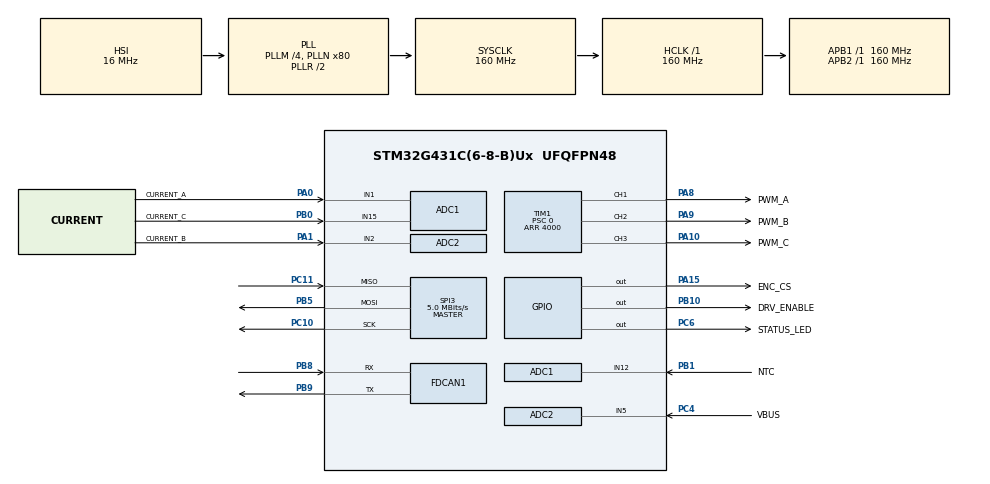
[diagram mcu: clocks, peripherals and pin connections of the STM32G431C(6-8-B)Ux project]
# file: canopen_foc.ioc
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ADC1.Channel-0\#ChannelRegularConversion=ADC_CHANNEL_1
ADC1.Channel-1\#ChannelRegularConversion=ADC_CHANNEL_15
ADC1.Channel-2\#ChannelRegularConversion=ADC_CHANNEL_12
ADC1.ClockPrescaler=ADC_CLOCK_SYNC_PCLK_DIV4
ADC1.DMAAccessMode=ADC_DMAACCESSMODE_12_10_BITS
ADC1.DMAContinuousRequests=ENABLE
ADC1.DiscontinuousConvMode=DISABLE
ADC1.EOCSelection=ADC_EOC_SEQ_CONV
ADC1.EnableInjectedConversion=ENABLE
ADC1.EnableRegularConversion=ENABLE
ADC1.ExternalTrigConv=ADC_EXTERNALTRIG_T1_TRGO
ADC1.ExternalTrigConvEdge=ADC_EXTERNALTRIGCONVEDGE_RISING
ADC1.ExternalTrigInjecConv=ADC_INJECTED_SOFTWARE_START
ADC1.ExternalTrigInjecConvEdge=ADC_EXTERNALTRIGINJECCONV_EDGE_NONE
ADC1.InjNumberOfConversion=2
ADC1.InjectedChannel-0\#ChannelInjectedConversion=ADC_CHANNEL_TEMPSENSOR_ADC1
ADC1.InjectedChannel-1\#ChannelInjectedConversion=ADC_CHANNEL_VREFINT
ADC1.InjectedOffsetNumber-0\#ChannelInjectedConversion=ADC_OFFSET_NONE
ADC1.InjectedOffsetNumber-1\#ChannelInjectedConversion=ADC_OFFSET_NONE
ADC1.InjectedRank-0\#ChannelInjectedConversion=1
ADC1.InjectedRank-1\#ChannelInjectedConversion=2
ADC1.InjectedSamplingTime-0\#ChannelInjectedConversion=ADC_SAMPLETIME_247CYCLES_5
ADC1.InjectedSamplingTime-1\#ChannelInjectedConversion=ADC_SAMPLETIME_247CYCLES_5
ADC1.Mode=ADC_DUALMODE_REGSIMULT
ADC1.NbrOfConversion=3
ADC1.NbrOfConversionFlag=1
ADC1.OffsetNumber-0\#ChannelRegularConversion=ADC_OFFSET_NONE
ADC1.OffsetNumber-1\#ChannelRegularConversion=ADC_OFFSET_NONE
ADC1.OffsetNumber-2\#ChannelRegularConversion=ADC_OFFSET_NONE
ADC1.Overrun=ADC_OVR_DATA_OVERWRITTEN
ADC1.Rank-0\#ChannelRegularConversion=1
ADC1.Rank-1\#ChannelRegularConversion=2
ADC1.Rank-2\#ChannelRegularConversion=3
ADC1.SamplingTime-0\#ChannelRegularConversion=ADC_SAMPLETIME_24CYCLES_5
ADC1.SamplingTime-1\#ChannelRegularConversion=ADC_SAMPLETIME_24CYCLES_5
ADC1.SamplingTime-2\#ChannelRegularConversion=ADC_SAMPLETIME_24CYCLES_5
ADC1.ScanConvMode=ADC_SCAN_ENABLE
ADC1.TwoSamplingDelay=ADC_TWOSAMPLINGDELAY_1CYCLE
ADC1.master=1
ADC2.Channel-0\#ChannelRegularConversion=ADC_CHANNEL_2
ADC2.Channel-1\#ChannelRegularConversion=ADC_CHANNEL_5
ADC2.Channel-2\#ChannelRegularConversion=ADC_CHANNEL_5
ADC2.ClockPrescaler=ADC_CLOCK_SYNC_PCLK_DIV4
ADC2.DMAContinuousRequests=ENABLE
ADC2.DiscontinuousConvMode=DISABLE
ADC2.EOCSelection=ADC_EOC_SEQ_CONV
ADC2.EnableRegularConversion=ENABLE
ADC2.ExternalTrigConv=ADC_SOFTWARE_START
ADC2.ExternalTrigConvEdge=ADC_EXTERNALTRIGCONVEDGE_NONE
ADC2.NbrOfConversion=3
ADC2.NbrOfConversionFlag=1
ADC2.OffsetNumber-0\#ChannelRegularConversion=ADC_OFFSET_NONE
ADC2.OffsetNumber-1\#ChannelRegularConversion=ADC_OFFSET_NONE
ADC2.OffsetNumber-2\#ChannelRegularConversion=ADC_OFFSET_NONE
ADC2.Overrun=ADC_OVR_DATA_OVERWRITTEN
ADC2.Rank-0\#ChannelRegularConversion=1
ADC2.Rank-1\#ChannelRegularConversion=2
ADC2.Rank-2\#ChannelRegularConversion=3
ADC2.SamplingTime-0\#ChannelRegularConversion=ADC_SAMPLETIME_24CYCLES_5
ADC2.SamplingTime-1\#ChannelRegularConversion=ADC_SAMPLETIME_24CYCLES_5
ADC2.SamplingTime-2\#ChannelRegularConversion=ADC_SAMPLETIME_24CYCLES_5
ADC2.ScanConvMode=ADC_SCAN_ENABLE
Dma.ADC1.0.Direction=DMA_PERIPH_TO_MEMORY
Dma.ADC1.0.EventEnable=DISABLE
Dma.ADC1.0.Instance=DMA1_Channel1
Dma.ADC1.0.MemDataAlignment=DMA_MDATAALIGN_WORD
Dma.ADC1.0.MemInc=DMA_MINC_ENABLE
Dma.ADC1.0.Mode=DMA_CIRCULAR
Dma.ADC1.0.PeriphDataAlignment=DMA_PDATAALIGN_WORD
Dma.ADC1.0.PeriphInc=DMA_PINC_DISABLE
Dma.ADC1.0.Polarity=HAL_DMAMUX_REQ_GEN_RISING
Dma.ADC1.0.Priority=DMA_PRIORITY_VERY_HIGH
Dma.ADC1.0.RequestNumber=1
Dma.ADC1.0.SignalID=NONE
Dma.ADC1.0.SyncEnable=DISABLE
Dma.ADC1.0.SyncPolarity=HAL_DMAMUX_SYNC_NO_EVENT
Dma.ADC1.0.SyncRequestNumber=1
Dma.ADC1.0.SyncSignalID=NONE
Dma.Request0=ADC1
FDCAN1.AutoRetransmission=ENABLE
FDCAN1.CalculateBaudRateData=5000000
FDCAN1.CalculateBaudRateNominal=1000000
FDCAN1.CalculateTimeQuantumData=6.25
FDCAN1.CalculateTimeQuantumNominal=31.25
FDCAN1.ClockDivider=FDCAN_CLOCK_DIV1
FDCAN1.DataPrescaler=1
FDCAN1.DataSyncJumpWidth=4
FDCAN1.DataTimeSeg1=23
FDCAN1.DataTimeSeg2=8
FDCAN1.ExtFiltersNbr=0
FDCAN1.FrameFormat=FDCAN_FRAME_FD_BRS
FDCAN1.Mode=FDCAN_MODE_NORMAL
FDCAN1.NominalPrescaler=5
FDCAN1.NominalSyncJumpWidth=4
FDCAN1.NominalTimeSeg1=25
FDCAN1.NominalTimeSeg2=6
FDCAN1.StdFiltersNbr=1
IWDG.Prescaler=IWDG_PRESCALER_32
IWDG.Reload=249
Mcu.Family=STM32G4
Mcu.Name=STM32G431C(6-8-B)Ux
Mcu.Package=UFQFPN48
NVIC.ADC1_2_IRQn=true\:2\:0\:false\:false\:true\:true\:true\:true
NVIC.DMA1_Channel1_IRQn=true\:2\:0\:false\:false\:true\:true\:true\:true
NVIC.FDCAN1_IT0_IRQn=true\:6\:0\:false\:false\:true\:true\:true\:true
NVIC.PriorityGroup=NVIC_PRIORITYGROUP_4
NVIC.TIM1_UP_TIM16_IRQn=true\:1\:0\:false\:false\:true\:true\:true\:true
NVIC.TIM6_DAC_IRQn=true\:15\:0\:false\:false\:true\:true\:true\:true
NVIC.TimeBase=TIM6_DAC_IRQn
NVIC.TimeBaseIP=TIM6
PA0.GPIO_Label=CURRENT_A
PA0.Mode=IN1-Single-Ended
PA0.Signal=ADC1_IN1
PA1.GPIO_Label=CURRENT_B
PA1.Mode=IN2-Single-Ended
PA1.Signal=ADC2_IN2
PA10.GPIO_Label=PWM_C
PA10.Signal=S_TIM1_CH3
PA13.Mode=Serial_Wire
PA13.Signal=SYS_JTMS-SWDIO
PA14.Mode=Serial_Wire
PA14.Signal=SYS_JTCK-SWCLK
PA15.GPIO_Label=ENC_CS
PA15.PinState=GPIO_PIN_SET
PA15.Signal=GPIO_Output
PA8.GPIO_Label=PWM_A
PA8.Signal=S_TIM1_CH1
PA9.GPIO_Label=PWM_B
PA9.Signal=S_TIM1_CH2
PB0.GPIO_Label=CURRENT_C
PB0.Mode=IN15-Single-Ended
PB0.Signal=ADC1_IN15
PB1.GPIO_Label=NTC
PB1.Mode=IN12-Single-Ended
PB1.Signal=ADC1_IN12
PB10.GPIO_Label=DRV_ENABLE
PB10.PinState=GPIO_PIN_RESET
PB10.Signal=GPIO_Output
PB5.Mode=Full_Duplex_Master
PB5.Signal=SPI3_MOSI
PB8.Mode=FDCAN_Activate
PB8.Signal=FDCAN1_RX
PB9.Mode=FDCAN_Activate
PB9.Signal=FDCAN1_TX
PC10.Mode=Full_Duplex_Master
PC10.Signal=SPI3_SCK
PC11.Mode=Full_Duplex_Master
PC11.Signal=SPI3_MISO
PC4.GPIO_Label=VBUS
PC4.Mode=IN5-Single-Ended
PC4.Signal=ADC2_IN5
PC6.GPIO_Label=STATUS_LED
PC6.PinState=GPIO_PIN_RESET
PC6.Signal=GPIO_Output
ProjectManager.HeapSize=0x0
ProjectManager.StackSize=0x1000
ProjectManager.TargetToolchain=CMake
RCC.ADC12Freq_Value=160000000
RCC.AHBFreq_Value=160000000
RCC.APB1Freq_Value=160000000
RCC.APB1TimFreq_Value=160000000
RCC.APB2Freq_Value=160000000
RCC.APB2TimFreq_Value=160000000
RCC.CortexFreq_Value=160000000
RCC.EXTERNAL_CLOCK_VALUE=12288000
RCC.FDCANClockSelection=RCC_FDCANCLKSOURCE_PCLK1
RCC.HCLKFreq_Value=160000000
RCC.HSE_VALUE=8000000
RCC.HSI48_VALUE=48000000
RCC.HSI_VALUE=16000000
RCC.LSE_VALUE=32768
RCC.PLLM=RCC_PLLM_DIV4
RCC.PLLN=80
RCC.PLLQ=RCC_PLLQ_DIV2
RCC.SYSCLKFreq_VALUE=160000000
RCC.SYSCLKSource=RCC_SYSCLKSOURCE_PLLCLK
RCC.USBFreq_Value=160000000
RCC.VCOOutputFreq_Value=320000000
SH.S_TIM1_CH1.0=TIM1_CH1,PWM Generation1 CH1
SH.S_TIM1_CH2.0=TIM1_CH2,PWM Generation2 CH2
SH.S_TIM1_CH3.0=TIM1_CH3,PWM Generation3 CH3
SPI3.BaudRatePrescaler=SPI_BAUDRATEPRESCALER_32
SPI3.CLKPhase=SPI_PHASE_2EDGE
SPI3.CLKPolarity=SPI_POLARITY_LOW
SPI3.CalculateBaudRate=5.0 MBits/s
SPI3.DataSize=SPI_DATASIZE_8BIT
SPI3.Direction=SPI_DIRECTION_2LINES
SPI3.Mode=SPI_MODE_MASTER
SPI3.NSS=SPI_NSS_SOFT
SPI3.VirtualType=VM_MASTER
TIM1.OffStateRunMode=TIM_OSSR_ENABLE
TIM1.OffStateIDLEMode=TIM_OSSI_ENABLE
TIM1.AutoReloadPreload=TIM_AUTORELOAD_PRELOAD_ENABLE
TIM1.Channel-PWM\ Generation1\ CH1=TIM_CHANNEL_1
TIM1.Channel-PWM\ Generation2\ CH2=TIM_CHANNEL_2
TIM1.Channel-PWM\ Generation3\ CH3=TIM_CHANNEL_3
TIM1.Channel-PWM\ Generation4\ No\ Output=TIM_CHANNEL_4
TIM1.CounterMode=TIM_COUNTERMODE_CENTERALIGNED1
TIM1.OCMode_PWM-PWM\ Generation4\ No\ Output=TIM_OCMODE_PWM2
TIM1.PeriodNoDither=4000
TIM1.Prescaler=0
TIM1.PulseNoDither_1=2000
TIM1.PulseNoDither_2=2000
TIM1.PulseNoDither_3=2000
TIM1.PulseNoDither_4=3920
TIM1.RepetitionCounter=1
TIM1.TIM_MasterOutputTrigger=TIM_TRGO_OC4REF
TIM7.Period=65535
TIM7.PeriodNoDither=65535
TIM7.Prescaler=160-1
VP_ADC1_TempSens_Input.Mode=IN-TempSens
VP_ADC1_Vref_Input.Mode=IN-Vrefint
VP_CORDIC_VS_CORDIC.Mode=CORDIC_Activate
VP_IWDG_VS_IWDG.Mode=IWDG_Activate
VP_SYS_VS_DBSignals.Mode=DisableDeadBatterySignals
VP_SYS_VS_tim6.Mode=TIM6
VP_TIM1_VS_ClockSourceINT.Mode=Internal
VP_TIM1_VS_no_output4.Mode=PWM Generation4 No Output
VP_TIM7_VS_ClockSourceINT.Mode=Enable_Timer
board=custom

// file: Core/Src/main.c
/* USER CODE BEGIN Header */
/**
  ******************************************************************************
  * @file           : main.c
  * @brief          : Main program body
  ******************************************************************************
  * @attention
  *
  * Copyright (c) 2026 STMicroelectronics.
  * All rights reserved.
  *
  * This software is licensed under terms that can be found in the LICENSE file
  * in the root directory of this software component.
  * If no LICENSE file comes with this software, it is provided AS-IS.
  *
  ******************************************************************************
  */
/* USER CODE END Header */
#include "main.h"
#include "adc.h"
#include "cordic.h"
#include "dma.h"
#include "fdcan.h"
#include "iwdg.h"
#include "spi.h"
#include "tim.h"
#include "gpio.h"

/* USER CODE BEGIN Includes */
#include "roller/app_bridge.h"

/* USER CODE END Includes */

void SystemClock_Config(void);

int main(void)
{

  /* MCU Configuration--------------------------------------------------------*/

  /* Reset of all peripherals, Initializes the Flash interface and the Systick. */
  HAL_Init();

  /* Configure the system clock */
  SystemClock_Config();

  /* Initialize all configured peripherals */
  MX_GPIO_Init();
  MX_DMA_Init();
  MX_ADC1_Init();
  MX_ADC2_Init();
  MX_SPI3_Init();
  MX_TIM1_Init();
  MX_TIM7_Init();
  MX_FDCAN1_Init();
  MX_IWDG_Init();
  MX_CORDIC_Init();
  /* USER CODE BEGIN 2 */
  roller_app_start();

  /* USER CODE END 2 */

  /* Infinite loop */
  while (1)
  {

  }
}

void SystemClock_Config(void)
{
  RCC_OscInitTypeDef RCC_OscInitStruct = {0};
  RCC_ClkInitTypeDef RCC_ClkInitStruct = {0};

  /** Configure the main internal regulator output voltage
  */
  HAL_PWREx_ControlVoltageScaling(PWR_REGULATOR_VOLTAGE_SCALE1_BOOST);

  /** Initializes the RCC Oscillators according to the specified parameters
  * in the RCC_OscInitTypeDef structure.
  */
  RCC_OscInitStruct.OscillatorType = RCC_OSCILLATORTYPE_HSI|RCC_OSCILLATORTYPE_LSI;
  RCC_OscInitStruct.HSIState = RCC_HSI_ON;
  RCC_OscInitStruct.HSICalibrationValue = RCC_HSICALIBRATION_DEFAULT;
  RCC_OscInitStruct.LSIState = RCC_LSI_ON;
  RCC_OscInitStruct.PLL.PLLState = RCC_PLL_ON;
  RCC_OscInitStruct.PLL.PLLSource = RCC_PLLSOURCE_HSI;
  RCC_OscInitStruct.PLL.PLLM = RCC_PLLM_DIV4;
  RCC_OscInitStruct.PLL.PLLN = 80;
  RCC_OscInitStruct.PLL.PLLP = RCC_PLLP_DIV2;
  RCC_OscInitStruct.PLL.PLLQ = RCC_PLLQ_DIV2;
  RCC_OscInitStruct.PLL.PLLR = RCC_PLLR_DIV2;
  if (HAL_RCC_OscConfig(&RCC_OscInitStruct) != HAL_OK)
  {
    Error_Handler();
  }

  /** Initializes the CPU, AHB and APB buses clocks
  */
  RCC_ClkInitStruct.ClockType = RCC_CLOCKTYPE_HCLK|RCC_CLOCKTYPE_SYSCLK
                              |RCC_CLOCKTYPE_PCLK1|RCC_CLOCKTYPE_PCLK2;
  RCC_ClkInitStruct.SYSCLKSource = RCC_SYSCLKSOURCE_PLLCLK;
  RCC_ClkInitStruct.AHBCLKDivider = RCC_SYSCLK_DIV1;
  RCC_ClkInitStruct.APB1CLKDivider = RCC_HCLK_DIV1;
  RCC_ClkInitStruct.APB2CLKDivider = RCC_HCLK_DIV1;

  if (HAL_RCC_ClockConfig(&RCC_ClkInitStruct, FLASH_LATENCY_4) != HAL_OK)
  {
    Error_Handler();
  }
}

void HAL_TIM_PeriodElapsedCallback(TIM_HandleTypeDef *htim)
{
  if (htim->Instance == TIM6)
  {
    HAL_IncTick();
  }
}

void Error_Handler(void)
{
  /* USER CODE BEGIN Error_Handler_Debug */
  roller_panic("HAL initialization");
  /* User can add his own implementation to report the HAL error return state */
  __disable_irq();
  while (1)
  {
  }
  /* USER CODE END Error_Handler_Debug */
}
